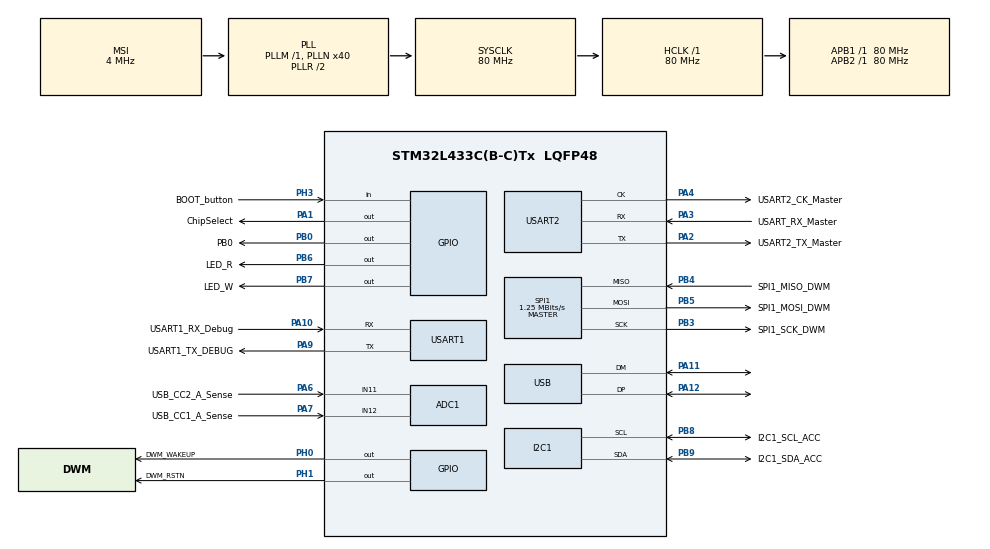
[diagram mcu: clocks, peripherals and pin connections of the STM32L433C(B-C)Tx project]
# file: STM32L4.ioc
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ADC1.Channel-0\#ChannelRegularConversion=ADC_CHANNEL_11
ADC1.NbrOfConversionFlag=1
ADC1.OffsetNumber-0\#ChannelRegularConversion=ADC_OFFSET_NONE
ADC1.Rank-0\#ChannelRegularConversion=1
ADC1.SamplingTime-0\#ChannelRegularConversion=ADC_SAMPLETIME_2CYCLES_5
ADC1.master=1
FREERTOS.Tasks01=defaultTask,24,128,StartDefaultTask,Default,NULL,Dynamic,NULL,NULL;Blink,8,256,StartBlink,As external,NULL,Dynamic,NULL,NULL;Accelerometer,24,512,StartAcc,As external,NULL,Dynamic,NULL,NULL;DWM,25,1024,StartDWM,As external,NULL,Dynamic,NULL,NULL
FREERTOS.configENABLE_FPU=1
FREERTOS.configTOTAL_HEAP_SIZE=16384
FREERTOS.configUSE_NEWLIB_REENTRANT=1
FREERTOS.configUSE_TICKLESS_IDLE=1
I2C1.Timing=0x10D19CE4
Mcu.Family=STM32L4
Mcu.Name=STM32L433C(B-C)Tx
Mcu.Package=LQFP48
NVIC.PriorityGroup=NVIC_PRIORITYGROUP_4
NVIC.TIM6_DAC_IRQn=true\:15\:0\:false\:false\:true\:false\:false\:true\:true
NVIC.TimeBase=TIM6_DAC_IRQn
NVIC.TimeBaseIP=TIM6
NVIC.USB_IRQn=true\:5\:0\:false\:false\:true\:true\:false\:true\:true
PA0.GPIO_Label=SYS_WKUP1_DWM
PA0.Mode=SYS_WakeUp0
PA0.Signal=SYS_WKUP1
PA1.GPIO_Label=ChipSelect
PA1.PinState=GPIO_PIN_SET
PA1.Signal=GPIO_Output
PA10.GPIO_Label=USART1_RX_Debug
PA10.Mode=Asynchronous
PA10.Signal=USART1_RX
PA11.Mode=Device
PA11.Signal=USB_DM
PA12.Mode=Device
PA12.Signal=USB_DP
PA13\ (JTMS-SWDIO).GPIO_Label=Debug-SWDIO
PA13\ (JTMS-SWDIO).Signal=SYS_JTMS-SWDIO
PA14\ (JTCK-SWCLK).GPIO_Label=Debug-SWCLK
PA14\ (JTCK-SWCLK).Signal=SYS_JTCK-SWCLK
PA2.GPIO_Label=USART2_TX_Master
PA2.Mode=Synchronous
PA2.Signal=USART2_TX
PA3.GPIO_Label=USART_RX_Master
PA3.Mode=Synchronous
PA3.Signal=USART2_RX
PA4.GPIO_Label=USART2_CK_Master
PA4.Mode=Synchronous
PA4.Signal=USART2_CK
PA5.GPIO_Label=Vbat_sense
PA5.Signal=ADCx_IN10
PA6.GPIO_Label=USB_CC2_A_Sense
PA6.Signal=ADCx_IN11
PA7.GPIO_Label=USB_CC1_A_Sense
PA7.Signal=ADCx_IN12
PA9.GPIO_Label=USART1_TX_DEBUG
PA9.Mode=Asynchronous
PA9.Signal=USART1_TX
PB0.GPIO_Label=PB0
PB0.Signal=GPIO_Output
PB3\ (JTDO-TRACESWO).GPIO_Label=SPI1_SCK_DWM
PB3\ (JTDO-TRACESWO).Mode=Full_Duplex_Master
PB3\ (JTDO-TRACESWO).Signal=SPI1_SCK
PB4\ (NJTRST).GPIO_Label=SPI1_MISO_DWM
PB4\ (NJTRST).Mode=Full_Duplex_Master
PB4\ (NJTRST).Signal=SPI1_MISO
PB5.GPIO_Label=SPI1_MOSI_DWM
PB5.Mode=Full_Duplex_Master
PB5.Signal=SPI1_MOSI
PB6.GPIO_Label=LED_R
PB6.Signal=GPIO_Output
PB7.GPIO_Label=LED_W
PB7.PinState=GPIO_PIN_RESET
PB7.Signal=GPIO_Output
PB8.GPIO_Label=I2C1_SCL_ACC
PB8.Mode=I2C
PB8.Signal=I2C1_SCL
PB9.GPIO_Label=I2C1_SDA_ACC
PB9.Mode=I2C
PB9.Signal=I2C1_SDA
PC13.GPIO_Label=SYS_WKUP2_ACC
PC13.Mode=SYS_WakeUp1
PC13.Signal=SYS_WKUP2
PC14-OSC32_IN\ (PC14).Mode=LSE-External-Oscillator
PC14-OSC32_IN\ (PC14).Signal=RCC_OSC32_IN
PC15-OSC32_OUT\ (PC15).Mode=LSE-External-Oscillator
PC15-OSC32_OUT\ (PC15).Signal=RCC_OSC32_OUT
PH0-OSC_IN\ (PH0).GPIO_Label=DWM_WAKEUP
PH0-OSC_IN\ (PH0).Signal=GPIO_Output
PH1-OSC_OUT\ (PH1).GPIO_Label=DWM_RSTN
PH1-OSC_OUT\ (PH1).GPIO_ModeDefaultOutputPP=GPIO_MODE_OUTPUT_OD
PH1-OSC_OUT\ (PH1).GPIO_PuPd=GPIO_NOPULL
PH1-OSC_OUT\ (PH1).Signal=GPIO_Output
PH3-BOOT0.GPIO_Label=BOOT_button
PH3-BOOT0.Signal=GPIO_Input
ProjectManager.HeapSize=0x200
ProjectManager.StackSize=0x400
ProjectManager.TargetToolchain=CMake
RCC.ADCFreq_Value=48000000
RCC.AHBFreq_Value=80000000
RCC.APB1Freq_Value=80000000
RCC.APB1TimFreq_Value=80000000
RCC.APB2Freq_Value=80000000
RCC.APB2TimFreq_Value=80000000
RCC.CK48CLockSelection=RCC_USBCLKSOURCE_HSI48
RCC.CortexFreq_Value=80000000
RCC.HCLKFreq_Value=80000000
RCC.HSE_VALUE=8000000
RCC.HSI48_VALUE=48000000
RCC.HSI_VALUE=16000000
RCC.LSE_Drive_CapabilityArg=+LSE_Drive_Capability
RCC.MSIAutoCalibration=ENABLED
RCC.MSI_VALUE=4000000
RCC.PLLN=40
RCC.PLLSAI1N=24
RCC.SYSCLKFreq_VALUE=80000000
RCC.SYSCLKSource=RCC_SYSCLKSOURCE_PLLCLK
RCC.USBFreq_Value=48000000
RCC.VCOOutputFreq_Value=160000000
SH.ADCx_IN10.0=ADC1_IN10
SH.ADCx_IN11.0=ADC1_IN11,IN11-Single-Ended
SH.ADCx_IN12.0=ADC1_IN12,IN12-Single-Ended
SPI1.BaudRatePrescaler=SPI_BAUDRATEPRESCALER_64
SPI1.CalculateBaudRate=1.25 MBits/s
SPI1.DataSize=SPI_DATASIZE_8BIT
SPI1.Direction=SPI_DIRECTION_2LINES
SPI1.Mode=SPI_MODE_MASTER
SPI1.VirtualType=VM_MASTER
USART1.VirtualMode-Asynchronous=VM_ASYNC
USART2.VirtualMode-Synchronous=VM_SYNC
USB_DEVICE.CLASS_NAME_FS=CDC
USB_DEVICE.USBD_DEBUG_LEVEL=2
USB_DEVICE.VirtualMode=Cdc
USB_DEVICE.VirtualModeFS=Cdc_FS
VP_FREERTOS_VS_CMSIS_V2.Mode=CMSIS_V2
VP_RCC_LSE.Mode=CRS SYNC Source LSE
VP_SYS_VS_tim6.Mode=TIM6
VP_USB_DEVICE_VS_USB_DEVICE_CDC_FS.Mode=CDC_FS
board=custom

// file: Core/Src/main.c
/* USER CODE BEGIN Header */
/**
  ******************************************************************************
  * @file           : main.c
  * @brief          : Main program body
  ******************************************************************************
  * @attention
  *
  * Copyright (c) 2026 STMicroelectronics.
  * All rights reserved.
  *
  * This software is licensed under terms that can be found in the LICENSE file
  * in the root directory of this software component.
  * If no LICENSE file comes with this software, it is provided AS-IS.
  *
  ******************************************************************************
  */
/* USER CODE END Header */
#include "main.h"
#include "cmsis_os.h"
#include "stm32l4xx_hal.h"
#include "usb_device.h"

/* USER CODE BEGIN Includes */
#include "lsm6dsv.h"
#include "blink.h"
#include "DWM3000.h"
/* USER CODE END Includes */

ADC_HandleTypeDef hadc1;

I2C_HandleTypeDef hi2c1;

SPI_HandleTypeDef hspi1;

UART_HandleTypeDef huart1;
USART_HandleTypeDef husart2;

/* Definitions for defaultTask */
osThreadId_t defaultTaskHandle;
const osThreadAttr_t defaultTask_attributes = {
  .name = "defaultTask",
  .stack_size = 128 * 4,
  .priority = (osPriority_t) osPriorityNormal,
};
/* Definitions for Blink */
osThreadId_t BlinkHandle;
const osThreadAttr_t Blink_attributes = {
  .name = "Blink",
  .stack_size = 256 * 4,
  .priority = (osPriority_t) osPriorityLow,
};
/* Definitions for Accelerometer */
osThreadId_t AccelerometerHandle;
const osThreadAttr_t Accelerometer_attributes = {
  .name = "Accelerometer",
  .stack_size = 512 * 4,
  .priority = (osPriority_t) osPriorityNormal,
};
/* Definitions for DWM */
osThreadId_t DWMHandle;
const osThreadAttr_t DWM_attributes = {
  .name = "DWM",
  .stack_size = 1024 * 4,
  .priority = (osPriority_t) osPriorityNormal1,
};

void SystemClock_Config(void);
static void MX_GPIO_Init(void);
static void MX_I2C1_Init(void);
static void MX_SPI1_Init(void);
static void MX_USART1_UART_Init(void);
static void MX_USART2_Init(void);
static void MX_ADC1_Init(void);
void StartDefaultTask(void *argument);
extern void StartBlink(void *argument);
extern void StartAcc(void *argument);
extern void StartDWM(void *argument);

int main(void)
{

  /* MCU Configuration--------------------------------------------------------*/

  /* Reset of all peripherals, Initializes the Flash interface and the Systick. */
  HAL_Init();

  /* Configure the system clock */
  SystemClock_Config();

  /* Initialize all configured peripherals */
  MX_GPIO_Init();
  MX_I2C1_Init();
  MX_SPI1_Init();
  MX_USART1_UART_Init();
  MX_USART2_Init();
  MX_ADC1_Init();

  /* Init scheduler */
  osKernelInitialize();

  /* Create the thread(s) */
  /* creation of defaultTask */
  defaultTaskHandle = osThreadNew(StartDefaultTask, NULL, &defaultTask_attributes);

  /* creation of Blink */
  BlinkHandle = osThreadNew(StartBlink, NULL, &Blink_attributes);

  /* creation of Accelerometer */
  AccelerometerHandle = osThreadNew(StartAcc, NULL, &Accelerometer_attributes);

  /* creation of DWM */
  DWMHandle = osThreadNew(StartDWM, NULL, &DWM_attributes);

  /* Start scheduler */
  osKernelStart();

  /* We should never get here as control is now taken by the scheduler */

  /* Infinite loop */
  while (1)
  {

  }
}

void SystemClock_Config(void)
{
  RCC_OscInitTypeDef RCC_OscInitStruct = {0};
  RCC_ClkInitTypeDef RCC_ClkInitStruct = {0};
  RCC_CRSInitTypeDef RCC_CRSInitStruct = {0};

  /** Configure the main internal regulator output voltage
  */
  if (HAL_PWREx_ControlVoltageScaling(PWR_REGULATOR_VOLTAGE_SCALE1) != HAL_OK)
  {
    Error_Handler();
  }

  /** Configure LSE Drive Capability
  */
  HAL_PWR_EnableBkUpAccess();
  __HAL_RCC_LSEDRIVE_CONFIG(RCC_LSEDRIVE_LOW);

  /** Initializes the RCC Oscillators according to the specified parameters
  * in the RCC_OscInitTypeDef structure.
  */
  RCC_OscInitStruct.OscillatorType = RCC_OSCILLATORTYPE_HSI48|RCC_OSCILLATORTYPE_LSE
                              |RCC_OSCILLATORTYPE_MSI;
  RCC_OscInitStruct.LSEState = RCC_LSE_ON;
  RCC_OscInitStruct.HSI48State = RCC_HSI48_ON;
  RCC_OscInitStruct.MSIState = RCC_MSI_ON;
  RCC_OscInitStruct.MSICalibrationValue = 0;
  RCC_OscInitStruct.MSIClockRange = RCC_MSIRANGE_6;
  RCC_OscInitStruct.PLL.PLLState = RCC_PLL_ON;
  RCC_OscInitStruct.PLL.PLLSource = RCC_PLLSOURCE_MSI;
  RCC_OscInitStruct.PLL.PLLM = 1;
  RCC_OscInitStruct.PLL.PLLN = 40;
  RCC_OscInitStruct.PLL.PLLP = RCC_PLLP_DIV7;
  RCC_OscInitStruct.PLL.PLLQ = RCC_PLLQ_DIV2;
  RCC_OscInitStruct.PLL.PLLR = RCC_PLLR_DIV2;
  if (HAL_RCC_OscConfig(&RCC_OscInitStruct) != HAL_OK)
  {
    Error_Handler();
  }

  /** Initializes the CPU, AHB and APB buses clocks
  */
  RCC_ClkInitStruct.ClockType = RCC_CLOCKTYPE_HCLK|RCC_CLOCKTYPE_SYSCLK
                              |RCC_CLOCKTYPE_PCLK1|RCC_CLOCKTYPE_PCLK2;
  RCC_ClkInitStruct.SYSCLKSource = RCC_SYSCLKSOURCE_PLLCLK;
  RCC_ClkInitStruct.AHBCLKDivider = RCC_SYSCLK_DIV1;
  RCC_ClkInitStruct.APB1CLKDivider = RCC_HCLK_DIV1;
  RCC_ClkInitStruct.APB2CLKDivider = RCC_HCLK_DIV1;

  if (HAL_RCC_ClockConfig(&RCC_ClkInitStruct, FLASH_LATENCY_4) != HAL_OK)
  {
    Error_Handler();
  }

  /** Enable MSI Auto calibration
  */
  HAL_RCCEx_EnableMSIPLLMode();

  /** Enable the SYSCFG APB clock
  */
  __HAL_RCC_CRS_CLK_ENABLE();

  /** Configures CRS
  */
  RCC_CRSInitStruct.Prescaler = RCC_CRS_SYNC_DIV1;
  RCC_CRSInitStruct.Source = RCC_CRS_SYNC_SOURCE_LSE;
  RCC_CRSInitStruct.Polarity = RCC_CRS_SYNC_POLARITY_RISING;
  RCC_CRSInitStruct.ReloadValue = __HAL_RCC_CRS_RELOADVALUE_CALCULATE(48000000,32768);
  RCC_CRSInitStruct.ErrorLimitValue = 34;
  RCC_CRSInitStruct.HSI48CalibrationValue = 32;

  HAL_RCCEx_CRSConfig(&RCC_CRSInitStruct);
}

static void MX_ADC1_Init(void)
{

  ADC_ChannelConfTypeDef sConfig = {0};

  /** Common config
  */
  hadc1.Instance = ADC1;
  hadc1.Init.ClockPrescaler = ADC_CLOCK_ASYNC_DIV1;
  hadc1.Init.Resolution = ADC_RESOLUTION_12B;
  hadc1.Init.DataAlign = ADC_DATAALIGN_RIGHT;
  hadc1.Init.ScanConvMode = ADC_SCAN_DISABLE;
  hadc1.Init.EOCSelection = ADC_EOC_SINGLE_CONV;
  hadc1.Init.LowPowerAutoWait = DISABLE;
  hadc1.Init.ContinuousConvMode = DISABLE;
  hadc1.Init.NbrOfConversion = 1;
  hadc1.Init.DiscontinuousConvMode = DISABLE;
  hadc1.Init.ExternalTrigConv = ADC_SOFTWARE_START;
  hadc1.Init.ExternalTrigConvEdge = ADC_EXTERNALTRIGCONVEDGE_NONE;
  hadc1.Init.DMAContinuousRequests = DISABLE;
  hadc1.Init.Overrun = ADC_OVR_DATA_PRESERVED;
  hadc1.Init.OversamplingMode = DISABLE;
  if (HAL_ADC_Init(&hadc1) != HAL_OK)
  {
    Error_Handler();
  }

  /** Configure Regular Channel
  */
  sConfig.Channel = ADC_CHANNEL_11;
  sConfig.Rank = ADC_REGULAR_RANK_1;
  sConfig.SamplingTime = ADC_SAMPLETIME_2CYCLES_5;
  sConfig.SingleDiff = ADC_SINGLE_ENDED;
  sConfig.OffsetNumber = ADC_OFFSET_NONE;
  sConfig.Offset = 0;
  if (HAL_ADC_ConfigChannel(&hadc1, &sConfig) != HAL_OK)
  {
    Error_Handler();
  }

}

static void MX_I2C1_Init(void)
{

  hi2c1.Instance = I2C1;
  hi2c1.Init.Timing = 0x10D19CE4;
  hi2c1.Init.OwnAddress1 = 0;
  hi2c1.Init.AddressingMode = I2C_ADDRESSINGMODE_7BIT;
  hi2c1.Init.DualAddressMode = I2C_DUALADDRESS_DISABLE;
  hi2c1.Init.OwnAddress2 = 0;
  hi2c1.Init.OwnAddress2Masks = I2C_OA2_NOMASK;
  hi2c1.Init.GeneralCallMode = I2C_GENERALCALL_DISABLE;
  hi2c1.Init.NoStretchMode = I2C_NOSTRETCH_DISABLE;
  if (HAL_I2C_Init(&hi2c1) != HAL_OK)
  {
    Error_Handler();
  }

  /** Configure Analogue filter
  */
  if (HAL_I2CEx_ConfigAnalogFilter(&hi2c1, I2C_ANALOGFILTER_ENABLE) != HAL_OK)
  {
    Error_Handler();
  }

  /** Configure Digital filter
  */
  if (HAL_I2CEx_ConfigDigitalFilter(&hi2c1, 0) != HAL_OK)
  {
    Error_Handler();
  }

}

static void MX_SPI1_Init(void)
{

  /* SPI1 parameter configuration*/
  hspi1.Instance = SPI1;
  hspi1.Init.Mode = SPI_MODE_MASTER;
  hspi1.Init.Direction = SPI_DIRECTION_2LINES;
  hspi1.Init.DataSize = SPI_DATASIZE_8BIT;
  hspi1.Init.CLKPolarity = SPI_POLARITY_LOW;
  hspi1.Init.CLKPhase = SPI_PHASE_1EDGE;
  hspi1.Init.NSS = SPI_NSS_SOFT;
  hspi1.Init.BaudRatePrescaler = SPI_BAUDRATEPRESCALER_64;
  hspi1.Init.FirstBit = SPI_FIRSTBIT_MSB;
  hspi1.Init.TIMode = SPI_TIMODE_DISABLE;
  hspi1.Init.CRCCalculation = SPI_CRCCALCULATION_DISABLE;
  hspi1.Init.CRCPolynomial = 7;
  hspi1.Init.CRCLength = SPI_CRC_LENGTH_DATASIZE;
  hspi1.Init.NSSPMode = SPI_NSS_PULSE_ENABLE;
  if (HAL_SPI_Init(&hspi1) != HAL_OK)
  {
    Error_Handler();
  }

}

static void MX_USART1_UART_Init(void)
{

  huart1.Instance = USART1;
  huart1.Init.BaudRate = 115200;
  huart1.Init.WordLength = UART_WORDLENGTH_8B;
  huart1.Init.StopBits = UART_STOPBITS_1;
  huart1.Init.Parity = UART_PARITY_NONE;
  huart1.Init.Mode = UART_MODE_TX_RX;
  huart1.Init.HwFlowCtl = UART_HWCONTROL_NONE;
  huart1.Init.OverSampling = UART_OVERSAMPLING_16;
  huart1.Init.OneBitSampling = UART_ONE_BIT_SAMPLE_DISABLE;
  huart1.AdvancedInit.AdvFeatureInit = UART_ADVFEATURE_NO_INIT;
  if (HAL_UART_Init(&huart1) != HAL_OK)
  {
    Error_Handler();
  }

}

static void MX_USART2_Init(void)
{

  husart2.Instance = USART2;
  husart2.Init.BaudRate = 115200;
  husart2.Init.WordLength = USART_WORDLENGTH_8B;
  husart2.Init.StopBits = USART_STOPBITS_1;
  husart2.Init.Parity = USART_PARITY_NONE;
  husart2.Init.Mode = USART_MODE_TX_RX;
  husart2.Init.CLKPolarity = USART_POLARITY_LOW;
  husart2.Init.CLKPhase = USART_PHASE_1EDGE;
  husart2.Init.CLKLastBit = USART_LASTBIT_DISABLE;
  if (HAL_USART_Init(&husart2) != HAL_OK)
  {
    Error_Handler();
  }

}

static void MX_GPIO_Init(void)
{
  GPIO_InitTypeDef GPIO_InitStruct = {0};

  /* GPIO Ports Clock Enable */
  __HAL_RCC_GPIOC_CLK_ENABLE();
  __HAL_RCC_GPIOH_CLK_ENABLE();
  __HAL_RCC_GPIOA_CLK_ENABLE();
  __HAL_RCC_GPIOB_CLK_ENABLE();

  /*Configure GPIO pin Output Level */
  HAL_GPIO_WritePin(GPIOH, DWM_WAKEUP_Pin|DWM_RSTN_Pin, GPIO_PIN_RESET);

  /*Configure GPIO pin Output Level */
  HAL_GPIO_WritePin(ChipSelect_GPIO_Port, ChipSelect_Pin, GPIO_PIN_SET);

  /*Configure GPIO pin Output Level */
  HAL_GPIO_WritePin(GPIOB, PB0_Pin|LED_R_Pin|LED_W_Pin, GPIO_PIN_RESET);

  /*Configure GPIO pin : DWM_WAKEUP_Pin */
  GPIO_InitStruct.Pin = DWM_WAKEUP_Pin;
  GPIO_InitStruct.Mode = GPIO_MODE_OUTPUT_PP;
  GPIO_InitStruct.Pull = GPIO_NOPULL;
  GPIO_InitStruct.Speed = GPIO_SPEED_FREQ_LOW;
  HAL_GPIO_Init(DWM_WAKEUP_GPIO_Port, &GPIO_InitStruct);

  /*Configure GPIO pin : DWM_RSTN_Pin */
  GPIO_InitStruct.Pin = DWM_RSTN_Pin;
  GPIO_InitStruct.Mode = GPIO_MODE_OUTPUT_OD;
  GPIO_InitStruct.Pull = GPIO_NOPULL;
  GPIO_InitStruct.Speed = GPIO_SPEED_FREQ_LOW;
  HAL_GPIO_Init(DWM_RSTN_GPIO_Port, &GPIO_InitStruct);

  /*Configure GPIO pin : ChipSelect_Pin */
  GPIO_InitStruct.Pin = ChipSelect_Pin;
  GPIO_InitStruct.Mode = GPIO_MODE_OUTPUT_PP;
  GPIO_InitStruct.Pull = GPIO_NOPULL;
  GPIO_InitStruct.Speed = GPIO_SPEED_FREQ_LOW;
  HAL_GPIO_Init(ChipSelect_GPIO_Port, &GPIO_InitStruct);

  /*Configure GPIO pins : PB0_Pin LED_R_Pin LED_W_Pin */
  GPIO_InitStruct.Pin = PB0_Pin|LED_R_Pin|LED_W_Pin;
  GPIO_InitStruct.Mode = GPIO_MODE_OUTPUT_PP;
  GPIO_InitStruct.Pull = GPIO_NOPULL;
  GPIO_InitStruct.Speed = GPIO_SPEED_FREQ_LOW;
  HAL_GPIO_Init(GPIOB, &GPIO_InitStruct);

  /*Configure GPIO pin : BOOT_button_Pin */
  GPIO_InitStruct.Pin = BOOT_button_Pin;
  GPIO_InitStruct.Mode = GPIO_MODE_INPUT;
  GPIO_InitStruct.Pull = GPIO_NOPULL;
  HAL_GPIO_Init(BOOT_button_GPIO_Port, &GPIO_InitStruct);

}

void StartDefaultTask(void *argument)
{
  /* init code for USB_DEVICE */
  MX_USB_DEVICE_Init();
  for(;;)
  {
    osDelay(1);
  }
}

void HAL_TIM_PeriodElapsedCallback(TIM_HandleTypeDef *htim)
{
  if (htim->Instance == TIM6)
  {
    HAL_IncTick();
  }
}

void Error_Handler(void)
{
  /* USER CODE BEGIN Error_Handler_Debug */
  /* User can add his own implementation to report the HAL error return state */
  __disable_irq();
  while (1)
  {
    HAL_GPIO_TogglePin(LED_R_GPIO_Port, LED_R_Pin);
    HAL_Delay(100);
  }
  /* USER CODE END Error_Handler_Debug */
}
